VERSION ""

NS_ :

BS_:

BU_: MoTeC_ECU

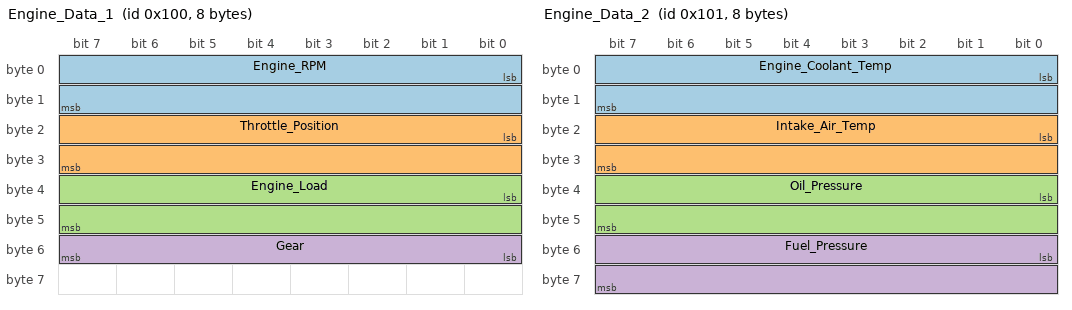
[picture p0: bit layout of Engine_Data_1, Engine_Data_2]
BO_ 256 Engine_Data_1: 8 MoTeC_ECU
 SG_ Engine_RPM : 0|16@1+ (1,0) [0|16000] "rpm" Vector__XXX
 SG_ Throttle_Position : 16|16@1+ (0.1,0) [0|100] "%" Vector__XXX
 SG_ Engine_Load : 32|16@1+ (0.1,0) [0|200] "%" Vector__XXX
 SG_ Gear : 48|8@1+ (1,0) [0|8] "" Vector__XXX

BO_ 257 Engine_Data_2: 8 MoTeC_ECU
 SG_ Engine_Coolant_Temp : 0|16@1+ (0.1,-40) [-40|200] "C" Vector__XXX
 SG_ Intake_Air_Temp : 16|16@1+ (0.1,-40) [-40|200] "C" Vector__XXX
 SG_ Oil_Pressure : 32|16@1+ (0.1,0) [0|1000] "kPa" Vector__XXX
 SG_ Fuel_Pressure : 48|16@1+ (0.1,0) [0|1000] "kPa" Vector__XXX

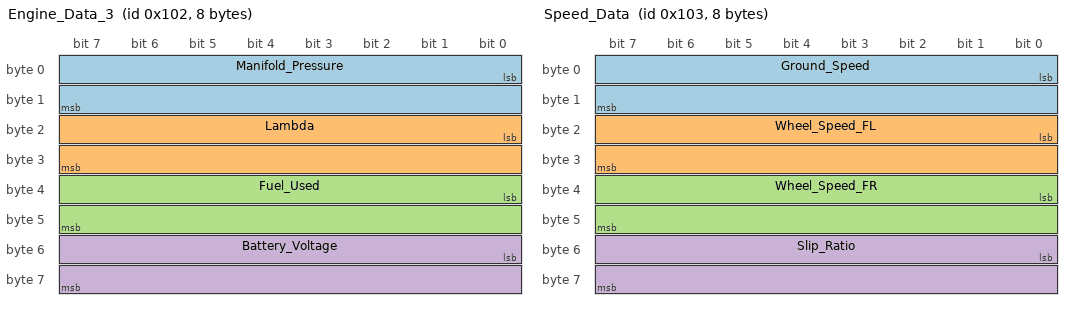
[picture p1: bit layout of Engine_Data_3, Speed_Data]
BO_ 258 Engine_Data_3: 8 MoTeC_ECU
 SG_ Manifold_Pressure : 0|16@1+ (0.1,0) [0|500] "kPa" Vector__XXX
 SG_ Lambda : 16|16@1+ (0.001,0) [0|2] "" Vector__XXX
 SG_ Fuel_Used : 32|16@1+ (0.1,0) [0|6500] "L" Vector__XXX
 SG_ Battery_Voltage : 48|16@1+ (0.01,0) [0|20] "V" Vector__XXX

BO_ 259 Speed_Data: 8 MoTeC_ECU
 SG_ Ground_Speed : 0|16@1+ (0.1,0) [0|500] "km/h" Vector__XXX
 SG_ Wheel_Speed_FL : 16|16@1+ (0.1,0) [0|500] "km/h" Vector__XXX
 SG_ Wheel_Speed_FR : 32|16@1+ (0.1,0) [0|500] "km/h" Vector__XXX
 SG_ Slip_Ratio : 48|16@1- (0.01,0) [-1|1] "" Vector__XXX

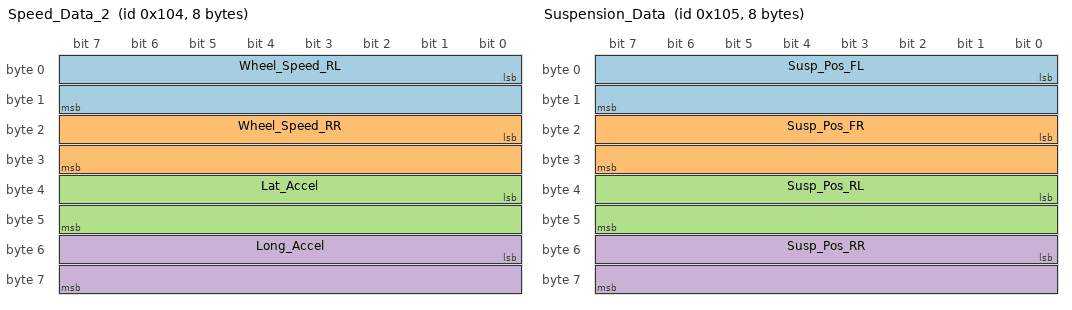
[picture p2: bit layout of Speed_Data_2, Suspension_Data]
BO_ 260 Speed_Data_2: 8 MoTeC_ECU
 SG_ Wheel_Speed_RL : 0|16@1+ (0.1,0) [0|500] "km/h" Vector__XXX
 SG_ Wheel_Speed_RR : 16|16@1+ (0.1,0) [0|500] "km/h" Vector__XXX
 SG_ Lat_Accel : 32|16@1- (0.001,0) [-5|5] "g" Vector__XXX
 SG_ Long_Accel : 48|16@1- (0.001,0) [-5|5] "g" Vector__XXX

BO_ 261 Suspension_Data: 8 MoTeC_ECU
 SG_ Susp_Pos_FL : 0|16@1- (0.1,0) [-200|200] "mm" Vector__XXX
 SG_ Susp_Pos_FR : 16|16@1- (0.1,0) [-200|200] "mm" Vector__XXX
 SG_ Susp_Pos_RL : 32|16@1- (0.1,0) [-200|200] "mm" Vector__XXX
 SG_ Susp_Pos_RR : 48|16@1- (0.1,0) [-200|200] "mm" Vector__XXX

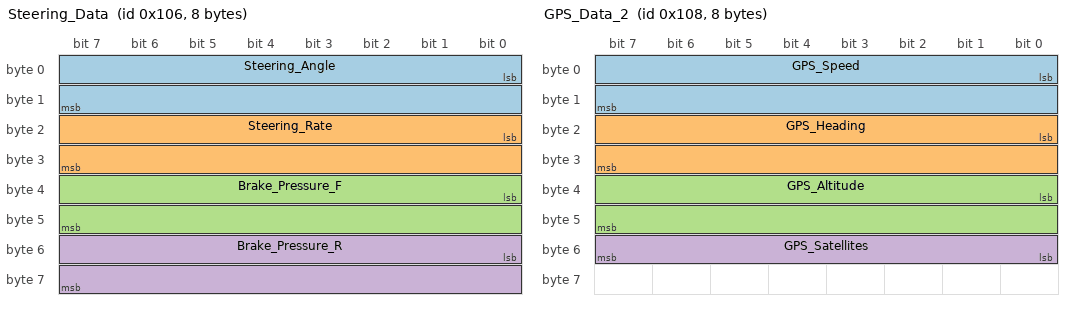
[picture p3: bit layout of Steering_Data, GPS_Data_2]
BO_ 262 Steering_Data: 8 MoTeC_ECU
 SG_ Steering_Angle : 0|16@1- (0.1,0) [-720|720] "deg" Vector__XXX
 SG_ Steering_Rate : 16|16@1- (0.1,0) [-1000|1000] "deg/s" Vector__XXX
 SG_ Brake_Pressure_F : 32|16@1+ (0.1,0) [0|20000] "kPa" Vector__XXX
 SG_ Brake_Pressure_R : 48|16@1+ (0.1,0) [0|20000] "kPa" Vector__XXX

BO_ 263 GPS_Data: 8 MoTeC_ECU
 SG_ GPS_Latitude : 0|32@1- (0.0000001,0) [-90|90] "deg" Vector__XXX
 SG_ GPS_Longitude : 32|32@1- (0.0000001,0) [-180|180] "deg" Vector__XXX

BO_ 264 GPS_Data_2: 8 MoTeC_ECU
 SG_ GPS_Speed : 0|16@1+ (0.01,0) [0|500] "km/h" Vector__XXX
 SG_ GPS_Heading : 16|16@1+ (0.01,0) [0|360] "deg" Vector__XXX
 SG_ GPS_Altitude : 32|16@1- (1,0) [-500|10000] "m" Vector__XXX
 SG_ GPS_Satellites : 48|8@1+ (1,0) [0|32] "" Vector__XXX

CM_ BU_ MoTeC_ECU "MoTeC ECU (M1, M150, M130, M84, M800 series)";
CM_ BO_ 256 "Primary engine data - RPM, throttle, load, gear";
CM_ BO_ 257 "Engine temperatures and pressures";
CM_ BO_ 258 "Manifold pressure, lambda, fuel consumption";
CM_ BO_ 259 "Ground speed and front wheel speeds";
CM_ BO_ 260 "Rear wheel speeds and accelerations";
CM_ BO_ 261 "Suspension position data";
CM_ BO_ 262 "Steering and brake data";
CM_ BO_ 263 "GPS position (if MoTeC GPS module connected)";
CM_ BO_ 264 "GPS speed, heading, altitude";

BA_DEF_ BO_ "GenMsgCycleTime" INT 0 10000;
BA_DEF_DEF_ "GenMsgCycleTime" 100;

BA_ "GenMsgCycleTime" BO_ 256 20;
BA_ "GenMsgCycleTime" BO_ 259 20;
BA_ "GenMsgCycleTime" BO_ 260 20;
BA_ "GenMsgCycleTime" BO_ 261 20;
BA_ "GenMsgCycleTime" BO_ 262 20;
